# STM32G474 register map
File version: 2.9
CPU: CM4 r0p1, little endian, MPU, FPU, 4 interrupt priority bits
Registers are 32-bit, read-write, reset 0x0 unless marked. A register's access mark holds for its fields unless they carry their own. Offsets are from the block's base; [hi:lo] are bit positions.

## CRC — Cyclic redundancy check calculation unit
Base 0x40023000
0x00 DR reset 0xFFFFFFFF — Data register
  [31:0] DR — Data register bits
0x00 DR8 8-bit reset 0xFF (alternate view of DR) — Data register - byte sized
  [7:0] DR8 — Data register bits
0x00 DR16 16-bit reset 0xFFFF (alternate view of DR) — Data register - half-word sized
  [15:0] DR16 — Data register bits
0x04 IDR — Independent data register
  [31:0] IDR — General-purpose 8-bit data register bits
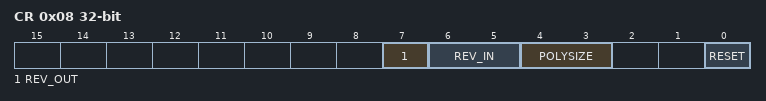
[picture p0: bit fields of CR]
0x08 CR access per field — Control register
  [7] REV_OUT rw — Reverse output data
    0=Normal (Bit order not affected); 1=Reversed (Bit reversed output)
  [6:5] REV_IN rw — Reverse input data
    0=Normal (Bit order not affected); 1=Byte (Bit reversal done by byte); 2=HalfWord (Bit reversal done by half-word); 3=Word (Bit reversal done by word)
  [4:3] POLYSIZE rw — Polynomial size
    0=32-bit polynomial; 1=16-bit polynomial; 2=8-bit polynomial; 3=7-bit polynomial
  [0] RESET wo — RESET bit
    1=Resets the CRC calculation unit and sets the data register to 0xFFFF FFFF
0x10 INIT reset 0xFFFFFFFF — Initial CRC value
  [31:0] INIT — Programmable initial CRC value
0x14 POL reset 0x4C11DB7 — polynomial
  [31:0] POL — Programmable polynomial

## IWDG — WinWATCHDOG
Base 0x40003000
0x00 KR 16-bit wo — Key register
  [15:0] KEY — Key value (write only, read 0x0000)
    0x5555=Unlock (Enable access to PR, RLR and WINR registers); 0xAAAA=Feed watchdog with RLR register value; 0xCCCC=Start the watchdog
0x04 PR 16-bit — Prescaler register
  [2:0] PR — Prescaler divider
    0=DivideBy4 (Divider /4); 1=DivideBy8 (Divider /8); 2=DivideBy16 (Divider /16); 3=DivideBy32 (Divider /32); 4=DivideBy64 (Divider /64); 5=DivideBy128 (Divider /128); other=DivideBy256 (Divider /256)
0x08 RLR 16-bit reset 0xFFF — Reload register
  [11:0] RL — Watchdog counter reload value
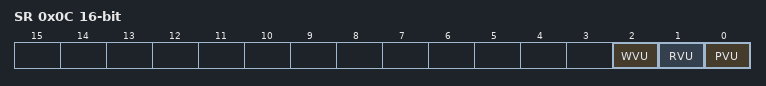
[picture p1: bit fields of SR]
0x0C SR 16-bit ro — Status register
  [2] WVU — Watchdog counter window value update
  [1] RVU — Watchdog counter reload value update
  [0] PVU — Watchdog prescaler value update
0x10 WINR 16-bit reset 0xFFF — Window register
  [11:0] WIN — Watchdog counter window value

## WWDG — System window watchdog
Base 0x40002C00
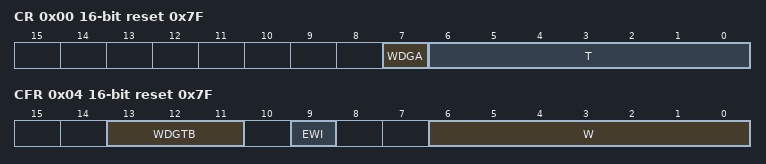
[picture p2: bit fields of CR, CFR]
0x00 CR 16-bit reset 0x7F — Control register
  [7] WDGA — Activation bit
    0=Disabled (Watchdog disabled); 1=Enabled (Watchdog enabled)
  [6:0] T — 7-bit counter (MSB to LSB)
0x04 CFR 16-bit reset 0x7F — Configuration register
  [13:11] WDGTB — Timer base
    0=Div1 (Counter clock (PCLK1 div 4096) div 1); 1=Div2 (Counter clock (PCLK1 div 4096) div 2); 2=Div4 (Counter clock (PCLK1 div 4096) div 4); 3=Div8 (Counter clock (PCLK1 div 4096) div 8); 4=Div16 (Counter clock (PCLK1 div 4096) div 16); 5=Div32 (Counter clock (PCLK1 div 4096) div 32); 6=Div64 (Counter clock (PCLK1 div 4096) div 64); 7=Div128 (Counter clock (PCLK1 div 4096) div 128)
  [9] EWI — Early wakeup interrupt
    on write: 1=Enable (interrupt occurs whenever the counter reaches the value 0x40)
  [6:0] W — 7-bit window value
0x08 SR 16-bit — Status register
  [0] EWIF write-0-clears — Early wakeup interrupt flag
    on read: 0=Finished (The EWI Interrupt Service Routine has been serviced); 1=Pending (The EWI Interrupt Service Routine has been triggered) | on write: 0=Finished (The EWI Interrupt Service Routine has been serviced)

## DBGMCU — Debug support
Base 0xE0042000
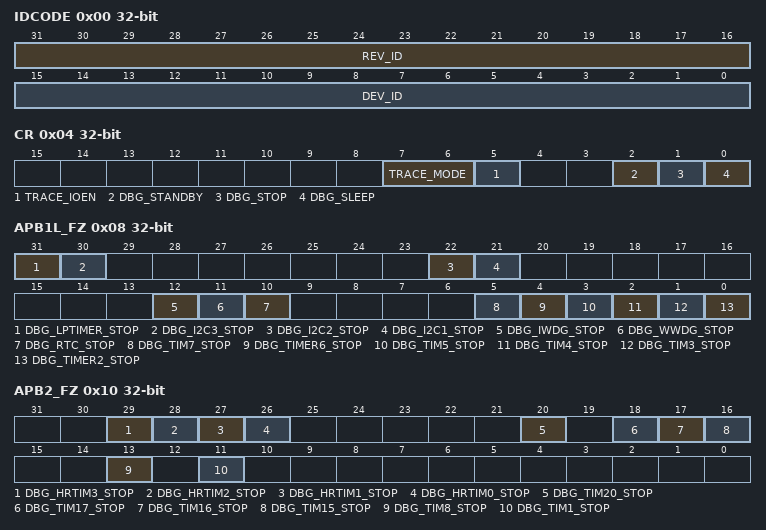
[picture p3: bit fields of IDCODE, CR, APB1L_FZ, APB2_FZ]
0x00 IDCODE ro — MCU Device ID Code Register
  [31:16] REV_ID — Revision Identifier
  [15:0] DEV_ID — Device Identifier
0x04 CR — Debug MCU Configuration Register
  [7:6] TRACE_MODE — Trace pin assignment control
  [5] TRACE_IOEN — Trace pin assignment control
  [2] DBG_STANDBY — Debug Standby Mode
  [1] DBG_STOP — Debug Stop Mode
  [0] DBG_SLEEP — Debug Sleep Mode
0x08 APB1L_FZ — APB Low Freeze Register 1
  [31] DBG_LPTIMER_STOP — LPTIM1 counter stopped when core is halted
  [30] DBG_I2C3_STOP — I2C3 SMBUS timeout mode stopped when core is halted
  [22] DBG_I2C2_STOP — I2C2 SMBUS timeout mode stopped when core is halted
  [21] DBG_I2C1_STOP — I2C1 SMBUS timeout mode stopped when core is halted
  [12] DBG_IWDG_STOP — Debug Independent Wachdog stopped when Core is halted
  [11] DBG_WWDG_STOP — Debug Window Wachdog stopped when Core is halted
  [10] DBG_RTC_STOP — Debug RTC stopped when Core is halted
  [5] DBG_TIM7_STOP — TIM7 counter stopped when core is halted
  [4] DBG_TIMER6_STOP — Debug Timer 6 stopped when Core is halted
  [3] DBG_TIM5_STOP — TIM5 counter stopped when core is halted
  [2] DBG_TIM4_STOP — TIM4 counter stopped when core is halted
  [1] DBG_TIM3_STOP — TIM3 counter stopped when core is halted
  [0] DBG_TIMER2_STOP — Debug Timer 2 stopped when Core is halted
0x0C APB1H_FZ — APB Low Freeze Register 2
  [1] DBG_I2C4_STOP
0x10 APB2_FZ — APB High Freeze Register
  [29] DBG_HRTIM3_STOP — DBG_HRTIM0_STOP
  [28] DBG_HRTIM2_STOP — DBG_HRTIM0_STOP
  [27] DBG_HRTIM1_STOP — DBG_HRTIM0_STOP
  [26] DBG_HRTIM0_STOP
  [20] DBG_TIM20_STOP — TIM20counter stopped when core is halted
  [18] DBG_TIM17_STOP — TIM17 counter stopped when core is halted
  [17] DBG_TIM16_STOP — TIM16 counter stopped when core is halted
  [16] DBG_TIM15_STOP — TIM15 counter stopped when core is halted
  [13] DBG_TIM8_STOP — TIM8 counter stopped when core is halted
  [11] DBG_TIM1_STOP — TIM1 counter stopped when core is halted
